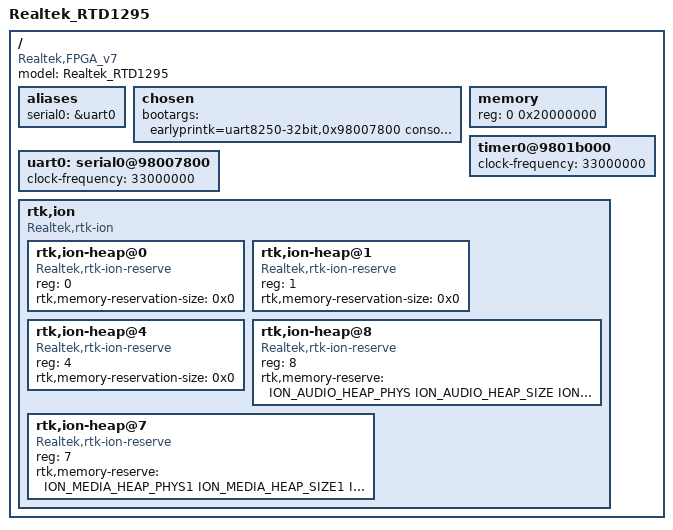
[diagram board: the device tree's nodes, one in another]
/dts-v1/;
#include "../../../../../include/soc/realtek/memory.h"

/memreserve/ SYS_BOOTCODE_MEMBASE       SYS_BOOTCODE_MEMSIZE        ; /* 0x00000000 ~ 0x0001efff */
/memreserve/ RPC_COMM_PHYS              RPC_COMM_SIZE               ; /* 0x0001f000 ~ 0x001fffff */
/memreserve/ ION_MEDIA_HEAP_PHYS1       ION_MEDIA_HEAP_SIZE1        ; /* 0x00200000 ~ 0x01afffff */
/memreserve/ ACPU_FIREWARE_PHYS         ACPU_FIREWARE_SIZE          ; /* 0x01b00000 ~ 0x01efffff */
/memreserve/ ION_AUDIO_HEAP_PHYS        ION_AUDIO_HEAP_SIZE         ; /* 0x01f00000 ~ 0x01ffdfff */
/memreserve/ RPC_RINGBUF_PHYS           RPC_RINGBUF_SIZE            ; /* 0x01ffe000 ~ 0x02001fff */
/memreserve/ ION_MEDIA_HEAP_PHYS2       ION_MEDIA_HEAP_SIZE2        ; /* 0x02002000 ~ 0x0fffffff */
/memreserve/ ACPU_IDMEM_PHYS            ACPU_IDMEM_SIZE             ; /* 0x10000000 ~ 0x10013fff */
/memreserve/ ACPU_BOOTCODE_PHYS         ACPU_BOOTCODE_SIZE          ; /* 0x10000000 ~ 0x10013fff */

#include "rtd-1295.dtsi"

/ {
	model= "Realtek_RTD1295";
	compatible = "Realtek,FPGA_v7", "Realtek,rtd-1295";

	aliases {
		serial0 = &uart0;
	};

	chosen {
		bootargs = "earlyprintk=uart8250-32bit,0x98007800 console=ttyS0,115200 loglevel=7 cma=16m@64m";
	};

	memory {
		device_type = "memory";
		reg = <0 0x20000000>;	/* 512 MB */
	};

	timer0@9801b000 {
		clock-frequency = <33000000>;
	};

	uart0: serial0@98007800 {
		clock-frequency = <33000000>;
	};

	rtk,ion {
		compatible = "Realtek,rtk-ion";
		#address-cells = <1>;
		#size-cells = <0>;
		rtk,ion-heap@0 {    /* SYSTEM_HEAP */
		    compatible = "Realtek,rtk-ion-reserve";
		    reg = <0>;
		    rtk,memory-reservation-size = <0x0>;
		};
		rtk,ion-heap@1 {    /* System contig */
		    compatible = "Realtek,rtk-ion-reserve";
		    reg = <1>;
		    rtk,memory-reservation-size = <0x0>;
		};
		rtk,ion-heap@4 {    /* DMA_HEAP */
		    compatible = "Realtek,rtk-ion-reserve";
		    reg = <4>;
		    rtk,memory-reservation-size = <0x0>;
		};
		rtk,ion-heap@8 {    /* Audio */
		    compatible = "Realtek,rtk-ion-reserve";
		    reg = <8>;
		    rtk,memory-reserve = <
		        ION_AUDIO_HEAP_PHYS ION_AUDIO_HEAP_SIZE ION_AUDIO_HEAP_FLAG
		        >;
		};
		rtk,ion-heap@7 {    /* TYPE_MEDIA */
		    compatible = "Realtek,rtk-ion-reserve";
		    reg = <7>;
		    rtk,memory-reserve = <
		        ION_MEDIA_HEAP_PHYS1 ION_MEDIA_HEAP_SIZE1 ION_MEDIA_HEAP_FLAG1
		        ION_MEDIA_HEAP_PHYS2 ION_MEDIA_HEAP_SIZE2 ION_MEDIA_HEAP_FLAG2
		        >;
		};
	};

};
